AUTOSAR XML (schema 00046)
standard types defined: uint8, uint8_DataConstr
package /ComponentTypes
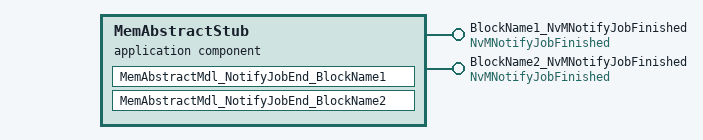
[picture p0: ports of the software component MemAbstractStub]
  application sw component type MemAbstractStub
    provide port BlockName1_NvMNotifyJobFinished: server-com-spec{operation=JobFinished, queue-length=1}, provided-interface=NvMNotifyJobFinished
    provide port BlockName2_NvMNotifyJobFinished: server-com-spec{operation=JobFinished, queue-length=1}, provided-interface=NvMNotifyJobFinished
    behavior MemAbstractStub_InternalBehavior
      operation invoked event OIT_MemAbstractMdl_NotifyJobEnd_BlockName1_NvMNotifyJobFinished_JobFinished_BlockName1_NvMNotifyJobFinished_JobFinished: start-on-event=MemAbstractMdl_NotifyJobEnd_BlockName1, operation=BlockName1_NvMNotifyJobFinished.JobFinished
      operation invoked event OIT_MemAbstractMdl_NotifyJobEnd_BlockName2_NvMNotifyJobFinished_JobFinished_BlockName2_NvMNotifyJobFinished_JobFinished: start-on-event=MemAbstractMdl_NotifyJobEnd_BlockName2, operation=BlockName2_NvMNotifyJobFinished.JobFinished
      runnable MemAbstractMdl_NotifyJobEnd_BlockName1
      runnable MemAbstractMdl_NotifyJobEnd_BlockName2
  swc implementation MemAbstractStub_Implementation: behavior=MemAbstractStub_InternalBehavior
    code-descriptors:
      code Default: artifact-descriptors=autosar-engineering-object={short-label=Default, category=SWSRC}
package /Predefined_DEV/ImplementationDataTypes
  impl type NvM_RequestResultType: compu {0=NVM_REQ_OK, 1=NVM_REQ_NOT_OK, 2=NVM_REQ_PENDING, 3=NVM_REQ_INTEGRITY_FAILED, 4=NVM_REQ_BLOCK_SKIPPED, 5=NVM_REQ_NV_INVALIDATED, 6=NVM_REQ_CANCELED, 7=NVM_REQ_REDUNDANCY_FAILED, 8=NVM_REQ_RESTORED_FROM_ROM}, implementation-data-type=uint8
  impl type NvM_ServiceIdType: compu {6=NVM_READ_BLOCK, 7=NVM_WRITE_BLOCK, 8=NVM_RESTORE_BLOCK_DEFAULTS, 9=NVM_ERASE_BLOCK, 11=NVM_INVALIDATE_NV_BLOCK, 12=NVM_READ_ALL}, implementation-data-type=uint8
package /Predefined_DEV/PortInterfaces
  client server interface NvMNotifyJobFinished: is-service=true
    operation JobFinished
      arg ServiceId: type=NvM_ServiceIdType, direction=IN, server-argument-impl-policy=USE-ARGUMENT-TYPE
      arg JobResult: type=NvM_RequestResultType, direction=IN, server-argument-impl-policy=USE-ARGUMENT-TYPE
